# STM32F446 register map
File version: 1.9
CPU: CM4 r0p1, little endian, MPU, FPU, 4 interrupt priority bits
Registers are 32-bit, read-write, reset 0x0 unless marked. A register's access mark holds for its fields unless they carry their own. Offsets are from the block's base; [hi:lo] are bit positions; {n}, {i} and the like mark numbered series.

## DBGMCU — Debug support
Base 0xE0042000
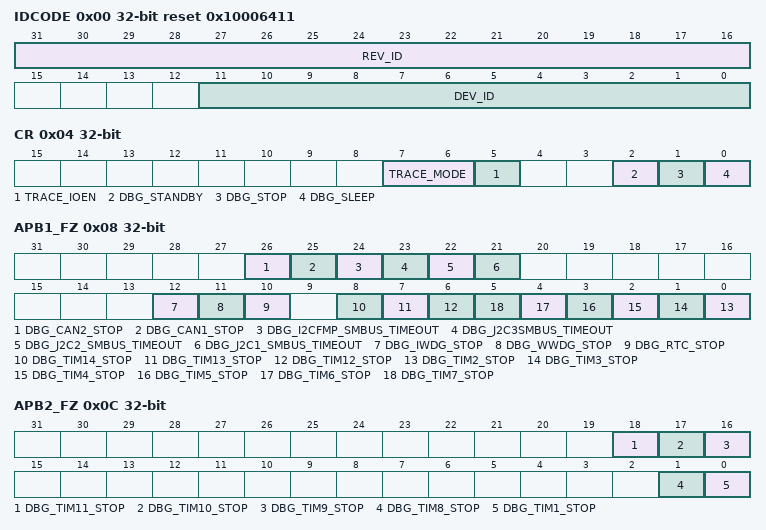
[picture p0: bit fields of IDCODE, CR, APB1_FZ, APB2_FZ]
0x00 IDCODE ro reset 0x10006411
  [31:16] REV_ID, [11:0] DEV_ID
0x04 CR — Control Register
  [7:6] TRACE_MODE, [5] TRACE_IOEN, [2] DBG_STANDBY, [1] DBG_STOP, [0] DBG_SLEEP
0x08 APB1_FZ — Debug MCU APB1 Freeze registe
  [26] DBG_CAN2_STOP
  [25] DBG_CAN1_STOP
  [24] DBG_I2CFMP_SMBUS_TIMEOUT — SMBUS timeout mode stopped when Core is halted
  [23] DBG_J2C3SMBUS_TIMEOUT
  [22] DBG_J2C2_SMBUS_TIMEOUT
  [21] DBG_J2C1_SMBUS_TIMEOUT
  [12] DBG_IWDG_STOP — DBG_IWDEG_STOP
  [11] DBG_WWDG_STOP
  [10] DBG_RTC_STOP — RTC stopped when Core is halted
  [8] DBG_TIM14_STOP
  [7] DBG_TIM13_STOP
  [6] DBG_TIM12_STOP
  [n-2] DBG_TIM{n}_STOP (n=2..7)
0x0C APB2_FZ — Debug MCU APB2 Freeze registe
  [18] DBG_TIM11_STOP — TIM11 counter stopped when core is halted
  [17] DBG_TIM10_STOP — TIM10 counter stopped when core is halted
  [16] DBG_TIM9_STOP — TIM9 counter stopped when core is halted
  [1] DBG_TIM8_STOP — TIM8 counter stopped when core is halted
  [0] DBG_TIM1_STOP — TIM1 counter stopped when core is halted

## GPIOH — General-purpose I/Os
Base 0x40021C00
Same registers: GPIOC 0x40020800, GPIOD 0x40020C00, GPIOE 0x40021000, GPIOF 0x40021400, GPIOG 0x40021800
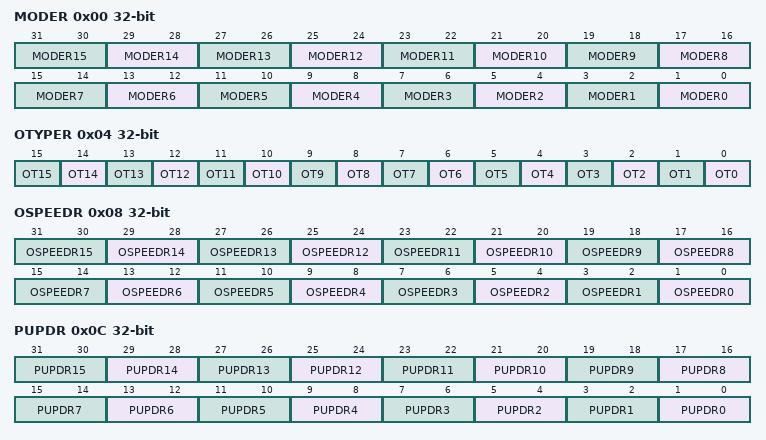
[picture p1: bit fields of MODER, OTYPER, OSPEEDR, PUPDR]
0x00 MODER — GPIO port mode register
  [2n+1:2n] MODER{n} (n=0..15) — Port x configuration pin {n}
    0=Input mode (reset state); 1=Output (General purpose output mode); 2=Alternate function mode; 3=Analog mode
0x04 OTYPER — GPIO port output type register
  [n] OT{n} (n=0..15) — Port x configuration pin {n}
    0=PushPull (Output push-pull (reset state)); 1=OpenDrain (Output open-drain)
0x08 OSPEEDR — GPIO port output speed register
  [2n+1:2n] OSPEEDR{n} (n=0..15) — Port x configuration pin {n}
    0=LowSpeed; 1=MediumSpeed; 2=HighSpeed; 3=VeryHighSpeed
0x0C PUPDR — GPIO port pull-up/pull-down register
  [2n+1:2n] PUPDR{n} (n=0..15) — Port x configuration pin {n}
    0=Floating (No pull-up, pull-down); 1=PullUp; 2=PullDown
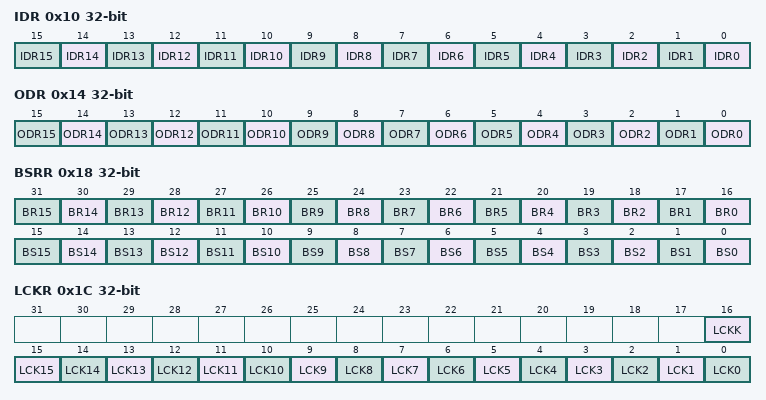
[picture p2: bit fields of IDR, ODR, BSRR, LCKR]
0x10 IDR ro — GPIO port input data register
  [n] IDR{n} (n=0..15) — Port input data pin {n}
    0=Low (Input is logic low); 1=High (Input is logic high)
0x14 ODR — GPIO port output data register
  [n] ODR{n} (n=0..15) — Port output data pin {n}
    0=Low (Set output to logic low); 1=High (Set output to logic high)
0x18 BSRR wo — GPIO port bit set/reset register
  [n+16] BR{n} (n=0..15) — Port x reset pin {n}
    1=Resets the corresponding ODRx bit
  [n] BS{n} (n=0..15) — Port x set pin {n}
    1=Set (Sets the corresponding ODRx bit)
0x1C LCKR — GPIO port configuration lock register
  [16] LCKK — Port x lock bit y (y= 0..15)
    0=NotActive (Port configuration lock key not active); 1=Active (Port configuration lock key active)
  [n] LCK{n} (n=0..15) — Port x lock pin {n}
    0=Unlocked (Port configuration not locked); 1=Locked (Port configuration locked)
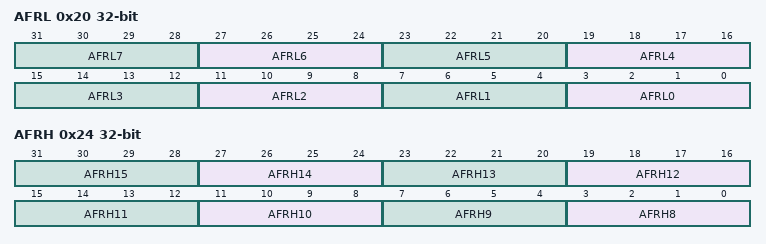
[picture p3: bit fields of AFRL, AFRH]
0x20 AFRL — GPIO alternate function low register
  [3:0] AFR{x} (x=L0,L1,L2,L3,L4,L5,L6,L7; step 4) — Alternate function selection for port x bit y (y = 0..7)
    {v}=AF{v} (v=0..15)
0x24 AFRH — GPIO alternate function high register
  [3:0] AFR{x} (x=H8,H9,H10,H11,H12,H13,H14,H15; step 4) — Alternate function selection for port x bit y (y = 8..15)
    {v}=AF{v} (v=0..15)

## GPIOB — General-purpose I/Os
Base 0x40020400
Registers as GPIOH; these are added or differ:
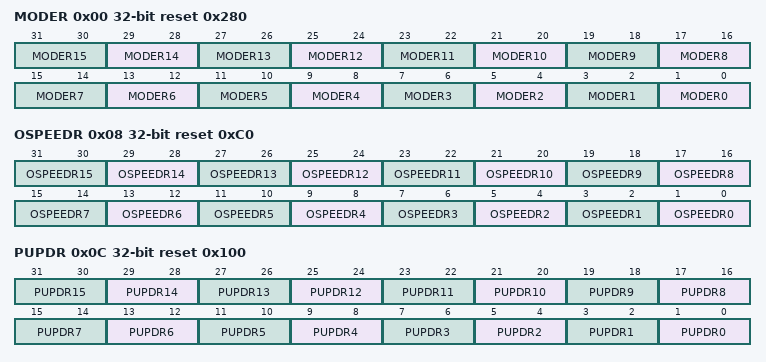
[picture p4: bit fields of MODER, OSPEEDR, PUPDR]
0x00 MODER reset 0x280 — GPIO port mode register
  [2n+1:2n] MODER{n} (n=0..15) — Port x configuration pin {n}
    0=Input mode (reset state); 1=Output (General purpose output mode); 2=Alternate function mode; 3=Analog mode
0x08 OSPEEDR reset 0xC0 — GPIO port output speed register
  [2n+1:2n] OSPEEDR{n} (n=0..15) — Port x configuration pin {n}
    0=LowSpeed; 1=MediumSpeed; 2=HighSpeed; 3=VeryHighSpeed
0x0C PUPDR reset 0x100 — GPIO port pull-up/pull-down register
  [2n+1:2n] PUPDR{n} (n=0..15) — Port x configuration pin {n}
    0=Floating (No pull-up, pull-down); 1=PullUp; 2=PullDown

## GPIOA — General-purpose I/Os
Base 0x40020000
Registers as GPIOH; these are added or differ:
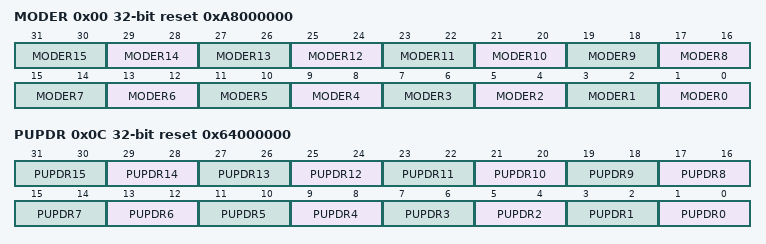
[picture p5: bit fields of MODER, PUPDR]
0x00 MODER reset 0xA8000000 — GPIO port mode register
  [2n+1:2n] MODER{n} (n=0..15) — Port x configuration pin {n}
    0=Input mode (reset state); 1=Output (General purpose output mode); 2=Alternate function mode; 3=Analog mode
0x0C PUPDR reset 0x64000000 — GPIO port pull-up/pull-down register
  [2n+1:2n] PUPDR{n} (n=0..15) — Port x configuration pin {n}
    0=Floating (No pull-up, pull-down); 1=PullUp; 2=PullDown
